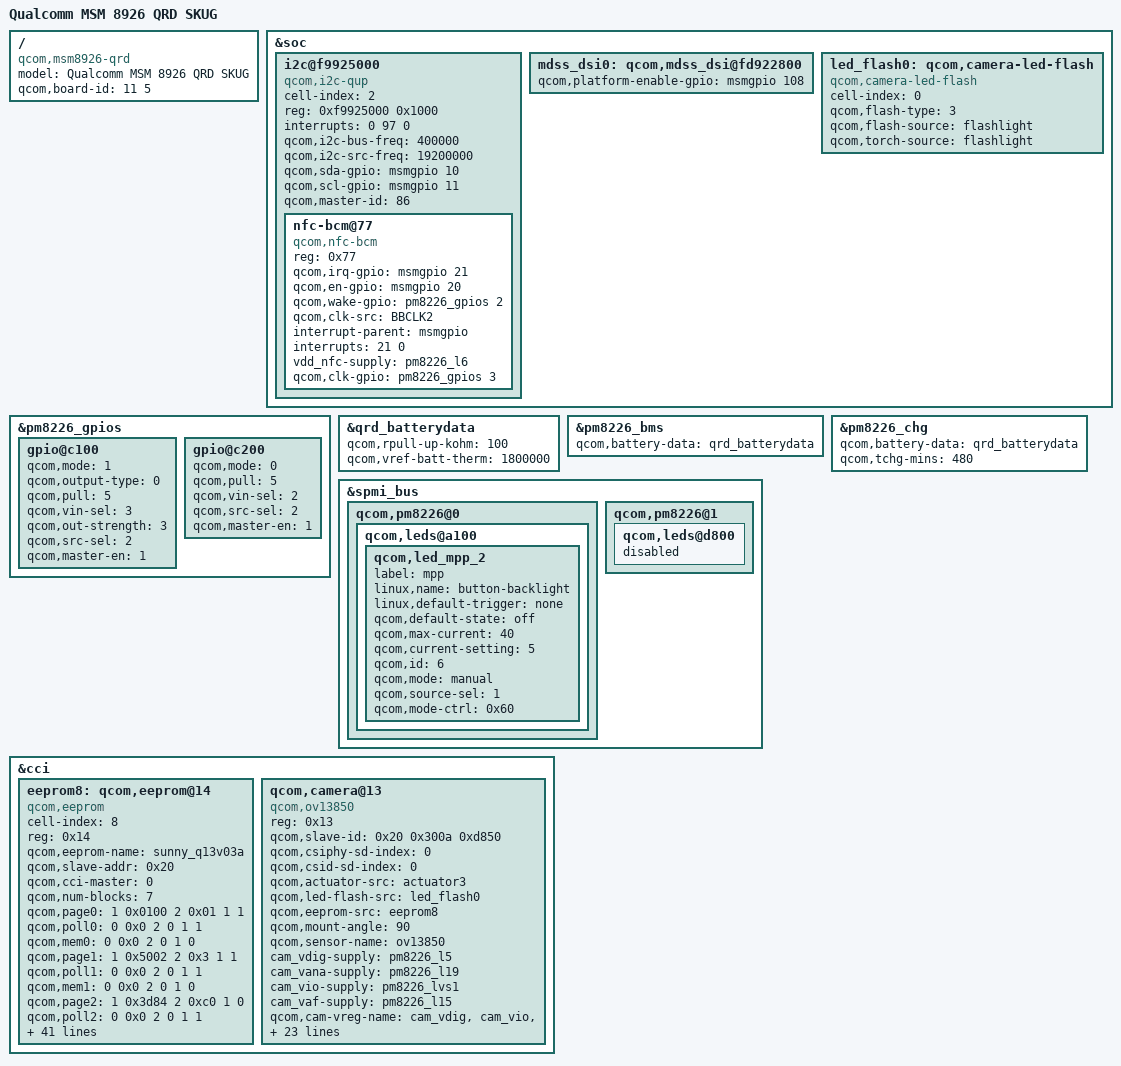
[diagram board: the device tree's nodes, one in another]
/* Copyright (c) 2013-2014, The Linux Foundation. All rights reserved.
 *
 * This program is free software; you can redistribute it and/or modify
 * it under the terms of the GNU General Public License version 2 and
 * only version 2 as published by the Free Software Foundation.
 *
 * This program is distributed in the hope that it will be useful,
 * but WITHOUT ANY WARRANTY; without even the implied warranty of
 * MERCHANTABILITY or FITNESS FOR A PARTICULAR PURPOSE.  See the
 * GNU General Public License for more details.
 */

/dts-v1/;
/include/ "msm8926-v1.dtsi"
/include/ "msm8926-qrd-skug.dtsi"

/ {
	model = "Qualcomm MSM 8926 QRD SKUG";
	compatible = "qcom,msm8926-qrd", "qcom,msm8926", "qcom,qrd";
	qcom,board-id = <11 5>;
};
/*xiangdong add for nfc begin*/
&soc {
	i2c@f9925000 { /* BLSP1 QUP3 */
		cell-index = <2>;
		compatible = "qcom,i2c-qup";
		reg = <0xf9925000 0x1000>;
		#address-cells = <1>;
		#size-cells = <0>;
		reg-names = "qup_phys_addr";
		interrupts = <0 97 0>;
		interrupt-names = "qup_err_intr";
		qcom,i2c-bus-freq = <400000>;
		qcom,i2c-src-freq = <19200000>;
		qcom,sda-gpio = <&msmgpio 10 0>;
		qcom,scl-gpio = <&msmgpio 11 0>;
		qcom,master-id = <86>;

		nfc-bcm@77 {
			compatible = "qcom,nfc-bcm";
			reg = <0x77>;
			qcom,irq-gpio = <&msmgpio 21 0x00>;
			qcom,en-gpio = <&msmgpio 20 0x00>;
			qcom,wake-gpio = <&pm8226_gpios 2 0>;
			qcom,clk-src = "BBCLK2";
			interrupt-parent = <&msmgpio>;
			interrupts = <21 0>;
			vdd_nfc-supply = <&pm8226_l6>;
			qcom,clk-gpio = <&pm8226_gpios 3 0>;
		};
	};
};
&pm8226_gpios {
	gpio@c100 { /* GPIO 2 */
		qcom,mode = <1>;		/* Digital output */
		qcom,output-type = <0>;		/* CMOS logic */
		qcom,pull = <5>;		/* QPNP_PIN_PULL_NO*/
		qcom,vin-sel = <3>;		/* QPNP_PIN_VIN3 */
		qcom,out-strength = <3>;	/* QPNP_PIN_OUT_STRENGTH_HIGH */
		qcom,src-sel = <2>;		/* QPNP_PIN_SEL_FUNC_1 */
		qcom,master-en = <1>;		/* Enable GPIO */
	};

	gpio@c200 { /* GPIO 3 */
		qcom,mode = <0>;		/* QPNP_PIN_MODE_DIG_IN */
		qcom,pull = <5>;		/* QPNP_PIN_PULL_NO */
		qcom,vin-sel = <2>;		/* QPNP_PIN_VIN2 */
		qcom,src-sel = <2>;		/* QPNP_PIN_SEL_FUNC_1 */
		qcom,master-en = <1>;
	};
};
/*xiangdong add for nfc end*/
/*xiangdong add for battery begin*/
&qrd_batterydata {
	qcom,rpull-up-kohm = <100>;
	qcom,vref-batt-therm = <1800000>;

	/include/ "batterydata-qrd-4v2-2000mah.dtsi"
	/include/ "TY_batterydata-qrd-4v35-2200mah.dtsi"
	/include/ "TY_batterydata-qrd-LS-4v33-2250mah.dtsi"
};

&pm8226_bms {
	qcom,battery-data = <&qrd_batterydata>;
};

&pm8226_chg {
	qcom,battery-data = <&qrd_batterydata>;
	qcom,tchg-mins = <480>;
};
/*xiangdong add for battery end*/
/*niuli add for 6 inch truly lcd pwm mode begin*/
/*mpp6 as pwm output--msm-pm8226.dtsi*/
&spmi_bus {
	qcom,pm8226@0 {
		qcom,leds@a100 {
			status = "okay";
			qcom,led_mpp_2 {
				label = "mpp";
				linux,name = "button-backlight";
				linux,default-trigger = "none";
				qcom,default-state = "off";
				qcom,max-current = <40>;
				qcom,current-setting = <5>;
				qcom,id = <6>;
				qcom,mode = "manual";
				qcom,source-sel = <1>;
				qcom,mode-ctrl = <0x60>;
				};
			};
     };

/*close wled control for current high*/
	qcom,pm8226@1 {
		qcom,leds@d800 {
			status = "disabled";
		};
	};
};
/*gpio108 as lcd enable--msm8226-mdss.dtsi*/
&soc {
	mdss_dsi0: qcom,mdss_dsi@fd922800 {
        qcom,platform-enable-gpio = <&msmgpio 108 0>;//niuli add for 108
	};
};

/*niuli add for 6 inch truly lcd pwm mode end*/
/*wang_gj add for gpio flashlight begin*/
&soc {
	led_flash0: qcom,camera-led-flash {
		cell-index = <0>;
		compatible = "qcom,camera-led-flash";
		qcom,flash-type = <3>;
		qcom,flash-source = <&flashlight>;
		qcom,torch-source = <&flashlight>;
	};
};
/*wang_gj add for gpio flashlight end*/
/*wang_gj add for gpio vana begin*/
&cci {
	eeprom8: qcom,eeprom@14{
		cell-index = <8>;
		reg = <0x14>;
		qcom,eeprom-name = "sunny_q13v03a";
		compatible = "qcom,eeprom";
		qcom,slave-addr = <0x20>;
		qcom,cci-master = <0>;
		qcom,num-blocks = <7>;
		qcom,page0 = <1 0x0100 2 0x01 1 1>;
		qcom,poll0 = <0 0x0 2 0 1 1>;
		qcom,mem0 = <0 0x0 2 0 1 0>;
		qcom,page1 = <1 0x5002 2 0x3 1 1>;
		qcom,poll1 = <0 0x0 2 0 1 1>;
		qcom,mem1 = <0 0x0 2 0 1 0>;
		qcom,page2 = <1 0x3d84 2 0xc0 1 0>;
		qcom,poll2 = <0 0x0 2 0 1 1>;
		qcom,mem2 = <0 0x0 2 0 1 0>;
		qcom,page3 = <1 0x3d88 2 0x7220 2 0>;
		qcom,poll3 = <0 0x0 2 0 1 1>;
		qcom,mem3 = <0 0x0 2 0 1 0>;
		qcom,page4 = <1 0x3d8a 2 0x7369 2 0>;
		qcom,poll4 = <0 0x0 2 0 1 1>;
		qcom,mem4 = <0 0x0 2 0 1 0>;
		qcom,page5 = <1 0x3d81 2 0x01 1 15>;
		qcom,poll5 = <0 0x0 2 0 1 1>;
		qcom,mem5 = <229 0x7220 2 0 1 0>;
		qcom,page6 = <1 0x5002 2 0x1 1 1>;
		qcom,poll6 = <0 0x0 2 0 1 1>;
		qcom,mem6 = <0 0x0 2 0 1 0>;

		cam_vdig-supply = <&pm8226_l5>;
		cam_vana-supply = <&pm8226_l19>;
		cam_vio-supply = <&pm8226_lvs1>;
		qcom,cam-vreg-name = "cam_vdig","cam_vana", "cam_vio";
		qcom,cam-vreg-type = <0 1 2>;
		qcom,cam-vreg-min-voltage = <1200000 2850000 0>;
		qcom,cam-vreg-max-voltage = <1200000 2850000 0>;
		qcom,cam-vreg-op-mode = <200000 80000 0>;
		qcom,gpio-no-mux = <0>;
		gpios = <&msmgpio 26 0>,
                        <&msmgpio 13 0>,/*gpio_vana*/
		        <&msmgpio 37 0>,
		        <&msmgpio 36 0>;
                qcom,gpio-vana = <1>;
		qcom,gpio-reset = <2>;
		qcom,gpio-standby = <3>;
		qcom,gpio-req-tbl-num = <0 1 2 3>;
		qcom,gpio-req-tbl-flags = <1 0 0 0>;
		qcom,gpio-req-tbl-label = "CAMIF_MCLK",
                        "CAM_VANA",
		        "CAM_RESET1",
		        "CAM_STANDBY";
		qcom,cam-power-seq-type = "sensor_vreg","sensor_vreg",
		        "sensor_vreg", "sensor_clk",
		        "sensor_gpio","sensor_gpio", "sensor_gpio";
		qcom,cam-power-seq-val = "cam_vdig","cam_vana",
		        "cam_vio", "sensor_cam_mclk",
                        "sensor_gpio_vana",
		        "sensor_gpio_reset",
		        "sensor_gpio_standby";
		qcom,cam-power-seq-cfg-val = <1 1 1 24000000 1 1 1>;
		qcom,cam-power-seq-delay = <1 1 1 5 5 5 10>;
	};

	qcom,camera@13{
		compatible = "qcom,ov13850";
		reg = <0x13>;
		qcom,slave-id = <0x20 0x300a 0xd850>;
		qcom,csiphy-sd-index = <0>;
		qcom,csid-sd-index = <0>;
		qcom,actuator-src = <&actuator3>;
		qcom,led-flash-src = <&led_flash0>;
		qcom,eeprom-src = <&eeprom8>;
		qcom,mount-angle = <90>;
		qcom,sensor-name = "ov13850";
		cam_vdig-supply = <&pm8226_l5>;
		cam_vana-supply = <&pm8226_l19>;
		cam_vio-supply = <&pm8226_lvs1>;
		cam_vaf-supply = <&pm8226_l15>;
		qcom,cam-vreg-name = "cam_vdig", "cam_vio", "cam_vana",
			"cam_vaf";
		qcom,cam-vreg-type = <0 1 0 0>;
		qcom,cam-vreg-min-voltage = <1200000 0 2850000 2800000>;
		qcom,cam-vreg-max-voltage = <1200000 0 2850000 2800000>;
		qcom,cam-vreg-op-mode = <200000 0 80000 100000>;
		qcom,gpio-no-mux = <0>;
		gpios = <&msmgpio 26 0>,
                        <&msmgpio 13 0>,/*gpio_vana*/
			<&msmgpio 37 0>,
			<&msmgpio 36 0>,
			<&msmgpio 15 0>;
                qcom,gpio-vana = <1>;
		qcom,gpio-reset = <2>;
		qcom,gpio-standby = <3>;
		qcom,gpio-af-pwdm = <4>;
		qcom,gpio-req-tbl-num = <0 1 2 3 4>;
		qcom,gpio-req-tbl-flags = <1 0 0 0 0>;
		qcom,gpio-req-tbl-label = "CAMIF_MCLK",
                        "CAM_VANA",
			"CAM_RESET1",
			"CAM_STANDBY",
			"CAM_AF_PWDM";
		qcom,csi-lane-assign = <0x4320>;
		qcom,csi-lane-mask = <0x1f>;
		qcom,sensor-position = <0>;
		qcom,sensor-mode = <1>;
		qcom,cci-master = <0>;
	};
};
/*wang_gj add for gpio vana end*/
